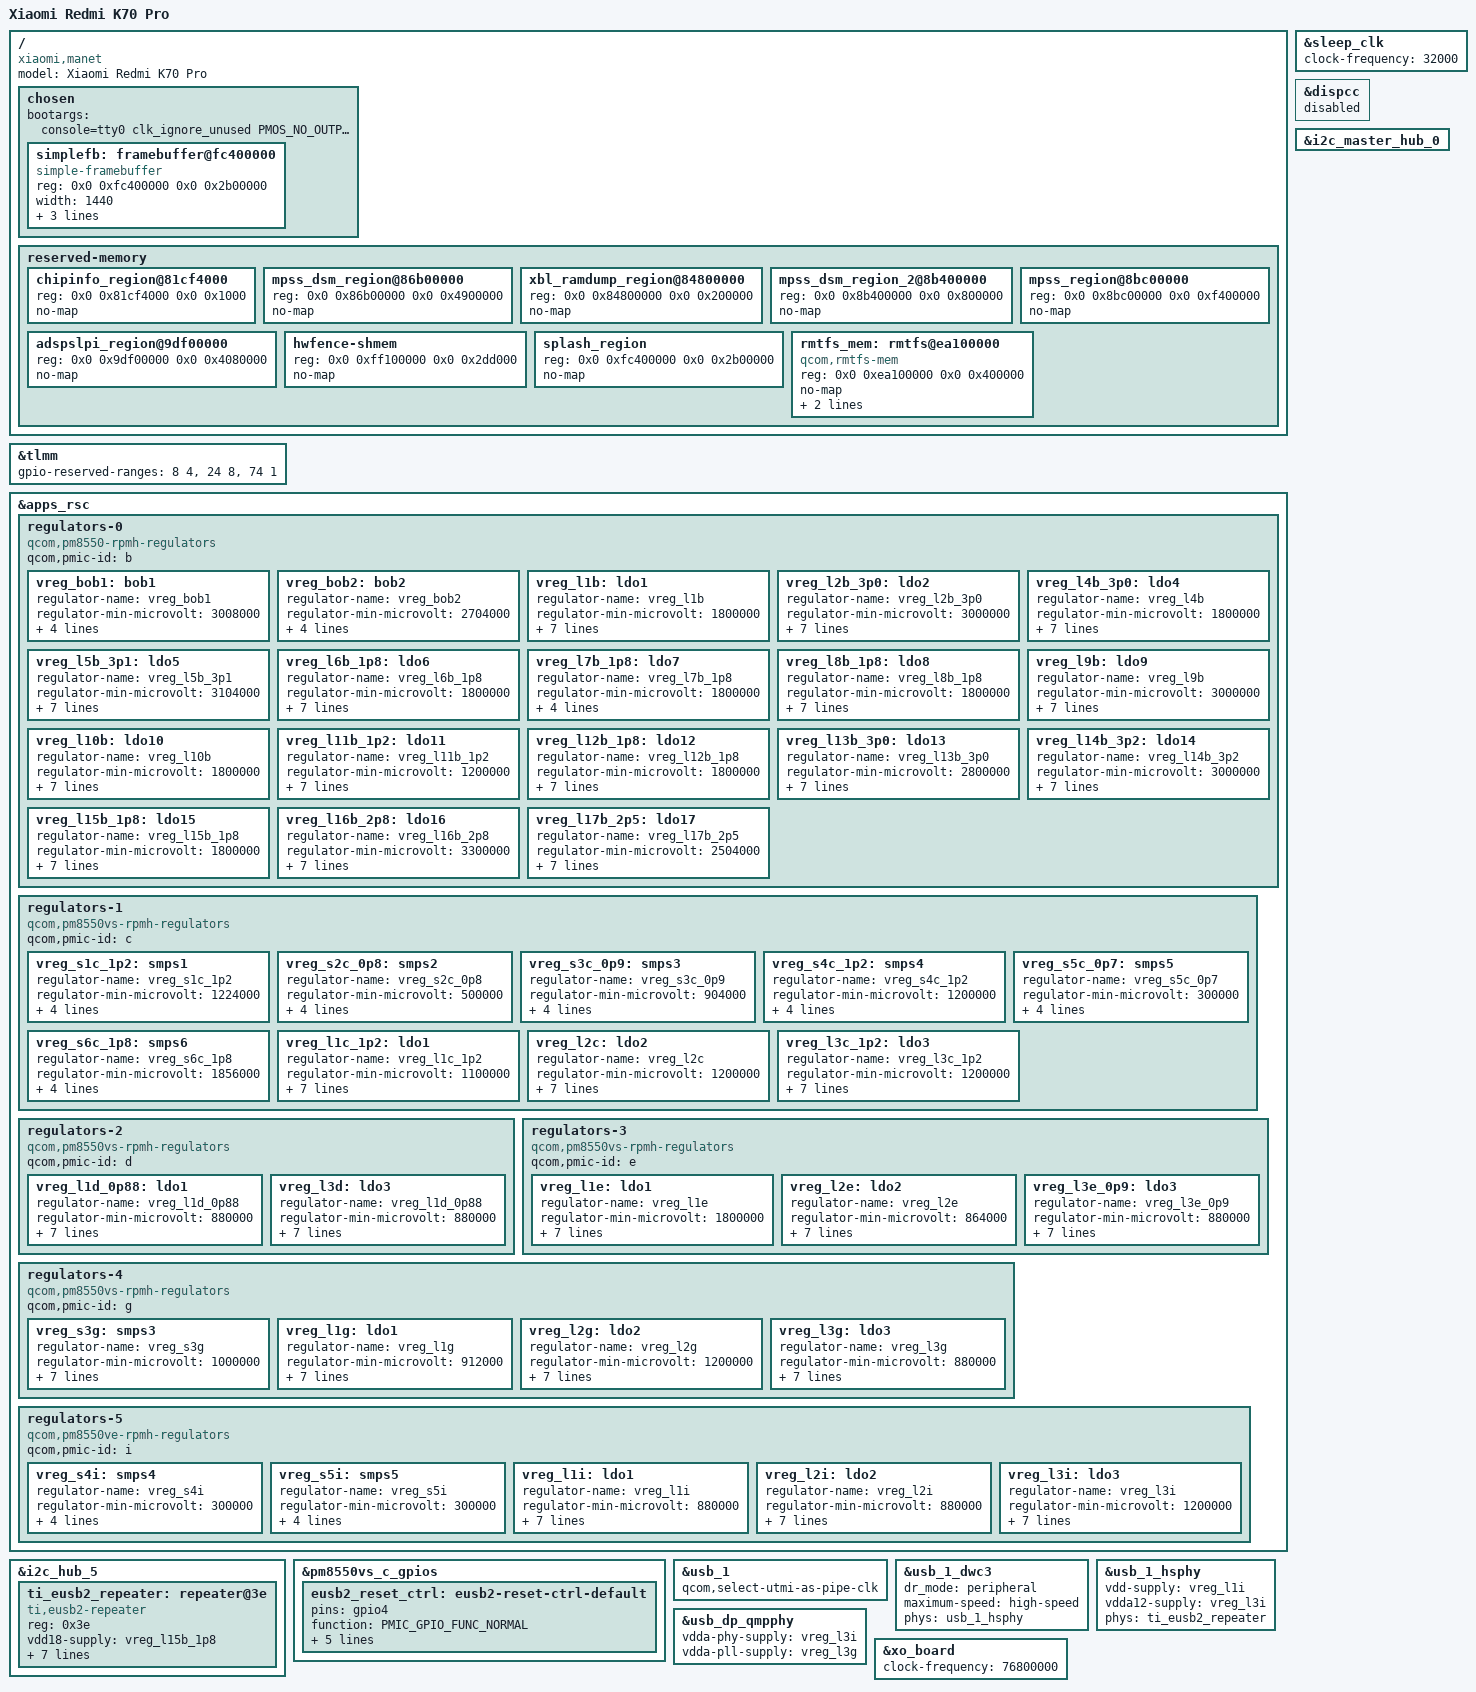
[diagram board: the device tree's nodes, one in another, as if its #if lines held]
// SPDX-License-Identifier: BSD-3-Clause
/*
 * Copyright (c) 2024, Igor Belwon <ibelwon@protonmail.com>
 */

/dts-v1/;

#include <dt-bindings/pinctrl/qcom,pmic-gpio.h>
#include <dt-bindings/regulator/qcom,rpmh-regulator.h>
#include "sm8650.dtsi"
#include "pm8550.dtsi"
#define PMK8550VE_SID 8
#include "pm8550ve.dtsi"
#include "pm8550vs.dtsi"
#include "pmk8550.dtsi"
#include "pmr735d_a.dtsi"

/delete-node/ &hwfence_shbuf;
/delete-node/ &rmtfs_mem;

#define ENABLE_SIMPLEFB true 

/ {
        model = "Xiaomi Redmi K70 Pro";
        compatible = "xiaomi,manet", "qcom,sm8650";

        chosen {
                #address-cells = <2>;
                #size-cells = <2>;
                ranges;

                bootargs = "console=tty0 clk_ignore_unused PMOS_NO_OUTPUT_REDIRECT";

#if ENABLE_SIMPLEFB
                simplefb: framebuffer@fc400000 {
                        compatible = "simple-framebuffer";
                        reg = <0x0 0xfc400000 0x0 0x2b00000>;
                        width = <1440>;
                        height = <3200>;
                        stride = <(1440 * 4)>;
                        format = "a8r8g8b8";
                };
#endif
        };

        reserved-memory {
                chipinfo_region@81cf4000 {
                    reg = <0x0 0x81cf4000 0x0 0x1000>;
                    no-map;
                };

                mpss_dsm_region@86b00000 {
                    reg = <0x0 0x86b00000 0x0 0x4900000>;
                    no-map;
                };

                xbl_ramdump_region@84800000 {
                    reg = <0x0 0x84800000 0x0 0x200000>;
                    no-map;
                };

                mpss_dsm_region_2@8b400000 {
                    reg = <0x0 0x8b400000 0x0 0x800000>;
                    no-map;
                };

                mpss_region@8bc00000 {
                    reg = <0x0 0x8bc00000 0x0 0xf400000>;
                    no-map;
                };

                adspslpi_region@9df00000 {
                    reg = <0x0 0x9df00000 0x0 0x4080000>;
                    no-map;
                };

                hwfence-shmem {
                    reg = <0x0 0xff100000 0x0 0x2dd000>;
                    no-map;
                };

                /* Hack for simplefb */
                splash_region {
                    reg = <0x0 0xfc400000 0x0 0x2b00000>;
                    no-map;
                };

                rmtfs_mem: rmtfs@ea100000 {
                    compatible = "qcom,rmtfs-mem";
                    reg = <0x0 0xea100000 0x0 0x400000>;
                    no-map;

                    qcom,client-id = <1>;
                    qcom,vmid = <QCOM_SCM_VMID_MSS_MSA>;
                };
        };
};

&sleep_clk {
	clock-frequency = <32000>;
};

&tlmm {
	gpio-reserved-ranges = <8 4>, <24 8>, <74 1>;
};

&apps_rsc {
	regulators-0 {
		compatible = "qcom,pm8550-rpmh-regulators";
		qcom,pmic-id = "b";

		vreg_bob1: bob1 {
			regulator-name = "vreg_bob1";
			regulator-min-microvolt = <3008000>;
			regulator-max-microvolt = <3960000>;
			regulator-initial-mode = <RPMH_REGULATOR_MODE_HPM>;
			regulator-always-on;
		};

		vreg_bob2: bob2 {
			regulator-name = "vreg_bob2";
			regulator-min-microvolt = <2704000>;
			regulator-max-microvolt = <3008000>;
			regulator-initial-mode = <RPMH_REGULATOR_MODE_HPM>;
			regulator-always-on;
		};

		vreg_l1b: ldo1 {
			regulator-name = "vreg_l1b";
			regulator-min-microvolt = <1800000>;
			regulator-max-microvolt = <1800000>;
			regulator-initial-mode = <RPMH_REGULATOR_MODE_HPM>;
			regulator-allow-set-load;
			regulator-allowed-modes = <RPMH_REGULATOR_MODE_LPM
						   RPMH_REGULATOR_MODE_HPM>;
			regulator-always-on;
		};

		vreg_l2b_3p0: ldo2 {
			regulator-name = "vreg_l2b_3p0";
			regulator-min-microvolt = <3000000>;
			regulator-max-microvolt = <3010000>;
			regulator-initial-mode = <RPMH_REGULATOR_MODE_HPM>;
			regulator-allow-set-load;
			regulator-allowed-modes = <RPMH_REGULATOR_MODE_LPM
						   RPMH_REGULATOR_MODE_HPM>;
			regulator-always-on;
		};

		vreg_l4b_3p0: ldo4 {
			regulator-name = "vreg_l4b";
			regulator-min-microvolt = <1800000>;
			regulator-max-microvolt = <1800000>;
			regulator-initial-mode = <RPMH_REGULATOR_MODE_HPM>;
			regulator-allow-set-load;
			regulator-allowed-modes = <RPMH_REGULATOR_MODE_LPM
						   RPMH_REGULATOR_MODE_HPM>;
			regulator-always-on;
		};

		vreg_l5b_3p1: ldo5 {
			regulator-name = "vreg_l5b_3p1";
			regulator-min-microvolt = <3104000>;
			regulator-max-microvolt = <3104000>;
			regulator-initial-mode = <RPMH_REGULATOR_MODE_HPM>;
			regulator-allow-set-load;
			regulator-allowed-modes = <RPMH_REGULATOR_MODE_LPM
						   RPMH_REGULATOR_MODE_HPM>;
			regulator-always-on;
		};

		vreg_l6b_1p8: ldo6 {
			regulator-name = "vreg_l6b_1p8";
			regulator-min-microvolt = <1800000>;
			regulator-max-microvolt = <3008000>;
			regulator-initial-mode = <RPMH_REGULATOR_MODE_HPM>;
			regulator-allow-set-load;
			regulator-allowed-modes = <RPMH_REGULATOR_MODE_LPM
						   RPMH_REGULATOR_MODE_HPM>;
			regulator-always-on;
		};

		vreg_l7b_1p8: ldo7 {
			regulator-name = "vreg_l7b_1p8";
			regulator-min-microvolt = <1800000>;
			regulator-max-microvolt = <3008000>;
			regulator-initial-mode = <RPMH_REGULATOR_MODE_HPM>;
			regulator-always-on;
		};

		vreg_l8b_1p8: ldo8 {
			regulator-name = "vreg_l8b_1p8";
			regulator-min-microvolt = <1800000>;
			regulator-max-microvolt = <1810000>;
			regulator-initial-mode = <RPMH_REGULATOR_MODE_HPM>;
			regulator-allow-set-load;
			regulator-allowed-modes = <RPMH_REGULATOR_MODE_LPM
						   RPMH_REGULATOR_MODE_HPM>;
			regulator-always-on;
		};

		vreg_l9b: ldo9 {
			regulator-name = "vreg_l9b";
			regulator-min-microvolt = <3000000>;
			regulator-max-microvolt = <3000000>;
			regulator-initial-mode = <RPMH_REGULATOR_MODE_HPM>;
			regulator-allow-set-load;
			regulator-allowed-modes = <RPMH_REGULATOR_MODE_LPM
						   RPMH_REGULATOR_MODE_HPM>;
			regulator-always-on;
		};

		vreg_l10b: ldo10 {
			regulator-name = "vreg_l10b";
			regulator-min-microvolt = <1800000>;
			regulator-max-microvolt = <1800000>;
			regulator-initial-mode = <RPMH_REGULATOR_MODE_HPM>;
			regulator-allow-set-load;
			regulator-allowed-modes = <RPMH_REGULATOR_MODE_LPM
						   RPMH_REGULATOR_MODE_HPM>;
			regulator-always-on;
		};

		vreg_l11b_1p2: ldo11 {
			regulator-name = "vreg_l11b_1p2";
			regulator-min-microvolt = <1200000>;
			regulator-max-microvolt = <1200000>;
			regulator-initial-mode = <RPMH_REGULATOR_MODE_HPM>;
			regulator-allow-set-load;
			regulator-allowed-modes = <RPMH_REGULATOR_MODE_LPM
						   RPMH_REGULATOR_MODE_HPM>;
			regulator-always-on;
		};

		vreg_l12b_1p8: ldo12 {
			regulator-name = "vreg_l12b_1p8";
			regulator-min-microvolt = <1800000>;
			regulator-max-microvolt = <1800000>;
			regulator-initial-mode = <RPMH_REGULATOR_MODE_HPM>;
			regulator-allow-set-load;
			regulator-allowed-modes = <RPMH_REGULATOR_MODE_LPM
						   RPMH_REGULATOR_MODE_HPM>;
			regulator-always-on;
		};

		vreg_l13b_3p0: ldo13 {
			regulator-name = "vreg_l13b_3p0";
			regulator-min-microvolt = <2800000>;
			regulator-max-microvolt = <2800000>;
			regulator-initial-mode = <RPMH_REGULATOR_MODE_HPM>;
			regulator-allow-set-load;
			regulator-allowed-modes = <RPMH_REGULATOR_MODE_LPM
						   RPMH_REGULATOR_MODE_HPM>;
			regulator-always-on;
		};

		vreg_l14b_3p2: ldo14 {
			regulator-name = "vreg_l14b_3p2";
			regulator-min-microvolt = <3000000>;
			regulator-max-microvolt = <3000000>;
			regulator-initial-mode = <RPMH_REGULATOR_MODE_HPM>;
			regulator-allow-set-load;
			regulator-allowed-modes = <RPMH_REGULATOR_MODE_LPM
						   RPMH_REGULATOR_MODE_HPM>;
			regulator-always-on;
		};

		vreg_l15b_1p8: ldo15 {
			regulator-name = "vreg_l15b_1p8";
			regulator-min-microvolt = <1800000>;
			regulator-max-microvolt = <1800000>;
			regulator-initial-mode = <RPMH_REGULATOR_MODE_HPM>;
			regulator-allow-set-load;
			regulator-allowed-modes = <RPMH_REGULATOR_MODE_LPM
						   RPMH_REGULATOR_MODE_HPM>;
			regulator-always-on;
		};

		vreg_l16b_2p8: ldo16 {
			regulator-name = "vreg_l16b_2p8";
			regulator-min-microvolt = <3300000>;
			regulator-max-microvolt = <3300000>;
			regulator-initial-mode = <RPMH_REGULATOR_MODE_HPM>;
			regulator-allow-set-load;
			regulator-allowed-modes = <RPMH_REGULATOR_MODE_LPM
						   RPMH_REGULATOR_MODE_HPM>;
			regulator-always-on;
		};

		vreg_l17b_2p5: ldo17 {
			regulator-name = "vreg_l17b_2p5";
			regulator-min-microvolt = <2504000>;
			regulator-max-microvolt = <2504000>;
			regulator-initial-mode = <RPMH_REGULATOR_MODE_HPM>;
			regulator-allow-set-load;
			regulator-allowed-modes = <RPMH_REGULATOR_MODE_LPM
						   RPMH_REGULATOR_MODE_HPM>;
			regulator-always-on;
		};
	};

	regulators-1 {
		compatible = "qcom,pm8550vs-rpmh-regulators";
		qcom,pmic-id = "c";

		vreg_s1c_1p2: smps1 {
			regulator-name = "vreg_s1c_1p2";
			regulator-min-microvolt = <1224000>;
			regulator-max-microvolt = <1348000>;
			regulator-initial-mode = <RPMH_REGULATOR_MODE_HPM>;
			regulator-always-on;
		};

		vreg_s2c_0p8: smps2 {
			regulator-name = "vreg_s2c_0p8";
			regulator-min-microvolt = <500000>;
			regulator-max-microvolt = <1036000>;
			regulator-initial-mode = <RPMH_REGULATOR_MODE_HPM>;
			regulator-always-on;
		};

		vreg_s3c_0p9: smps3 {
			regulator-name = "vreg_s3c_0p9";
			regulator-min-microvolt = <904000>;
			regulator-max-microvolt = <1064000>;
			regulator-initial-mode = <RPMH_REGULATOR_MODE_HPM>;
			regulator-always-on;
		};

		vreg_s4c_1p2: smps4 {
			regulator-name = "vreg_s4c_1p2";
			regulator-min-microvolt = <1200000>;
			regulator-max-microvolt = <1280000>;
			regulator-initial-mode = <RPMH_REGULATOR_MODE_HPM>;
			regulator-always-on;
		};

		vreg_s5c_0p7: smps5 {
			regulator-name = "vreg_s5c_0p7";
			regulator-min-microvolt = <300000>;
			regulator-max-microvolt = <900000>;
			regulator-initial-mode = <RPMH_REGULATOR_MODE_HPM>;
			regulator-always-on;
		};

		vreg_s6c_1p8: smps6 {
			regulator-name = "vreg_s6c_1p8";
			regulator-min-microvolt = <1856000>;
			regulator-max-microvolt = <2000000>;
			regulator-initial-mode = <RPMH_REGULATOR_MODE_HPM>;
			regulator-always-on;
		};

		vreg_l1c_1p2: ldo1 {
			regulator-name = "vreg_l1c_1p2";
			regulator-min-microvolt = <1100000>;
			regulator-max-microvolt = <1200000>;
			regulator-initial-mode = <RPMH_REGULATOR_MODE_HPM>;
			regulator-allow-set-load;
			regulator-allowed-modes = <RPMH_REGULATOR_MODE_LPM
						   RPMH_REGULATOR_MODE_HPM>;
			regulator-always-on;
		};

		vreg_l2c: ldo2 {
			regulator-name = "vreg_l2c";
			regulator-min-microvolt = <1200000>;
			regulator-max-microvolt = <1200000>;
			regulator-initial-mode = <RPMH_REGULATOR_MODE_HPM>;
			regulator-allow-set-load;
			regulator-allowed-modes = <RPMH_REGULATOR_MODE_LPM
						   RPMH_REGULATOR_MODE_HPM>;
			regulator-always-on;
		};

		vreg_l3c_1p2: ldo3 {
			regulator-name = "vreg_l3c_1p2";
			regulator-min-microvolt = <1200000>;
			regulator-max-microvolt = <1200000>;
			regulator-initial-mode = <RPMH_REGULATOR_MODE_HPM>;
			regulator-allow-set-load;
			regulator-allowed-modes = <RPMH_REGULATOR_MODE_LPM
						   RPMH_REGULATOR_MODE_HPM>;
			regulator-always-on;
		};
	};

	regulators-2 {
		compatible = "qcom,pm8550vs-rpmh-regulators";
		qcom,pmic-id = "d";

		vreg_l1d_0p88: ldo1 {
			regulator-name = "vreg_l1d_0p88";
			regulator-min-microvolt = <880000>;
			regulator-max-microvolt = <920000>;
			regulator-initial-mode = <RPMH_REGULATOR_MODE_HPM>;
			regulator-allow-set-load;
			regulator-allowed-modes = <RPMH_REGULATOR_MODE_LPM
						   RPMH_REGULATOR_MODE_HPM>;
			regulator-always-on;
		};

		vreg_l3d: ldo3 {
			regulator-name = "vreg_l1d_0p88";
			regulator-min-microvolt = <880000>;
			regulator-max-microvolt = <920000>;
			regulator-initial-mode = <RPMH_REGULATOR_MODE_HPM>;
			regulator-allow-set-load;
			regulator-allowed-modes = <RPMH_REGULATOR_MODE_LPM
						   RPMH_REGULATOR_MODE_HPM>;
			regulator-always-on;
		};
	};

	regulators-3 {
		compatible = "qcom,pm8550vs-rpmh-regulators";
		qcom,pmic-id = "e";

		vreg_l1e: ldo1 {
			regulator-name = "vreg_l1e";
			regulator-min-microvolt = <1800000>;
			regulator-max-microvolt = <1800000>;
			regulator-initial-mode = <RPMH_REGULATOR_MODE_HPM>;
			regulator-allow-set-load;
			regulator-allowed-modes = <RPMH_REGULATOR_MODE_LPM
						   RPMH_REGULATOR_MODE_HPM>;
			regulator-always-on;
		};

		vreg_l2e: ldo2 {
			regulator-name = "vreg_l2e";
			regulator-min-microvolt = <864000>;
			regulator-max-microvolt = <972000>;
			regulator-initial-mode = <RPMH_REGULATOR_MODE_HPM>;
			regulator-allow-set-load;
			regulator-allowed-modes = <RPMH_REGULATOR_MODE_LPM
						   RPMH_REGULATOR_MODE_HPM>;
			regulator-always-on;
		};

		vreg_l3e_0p9: ldo3 {
			regulator-name = "vreg_l3e_0p9";
			regulator-min-microvolt = <880000>;
			regulator-max-microvolt = <920000>;
			regulator-initial-mode = <RPMH_REGULATOR_MODE_HPM>;
			regulator-allow-set-load;
			regulator-allowed-modes = <RPMH_REGULATOR_MODE_LPM
						   RPMH_REGULATOR_MODE_HPM>;
			regulator-always-on;
		};
	};

	regulators-4 {
		compatible = "qcom,pm8550vs-rpmh-regulators";
		qcom,pmic-id = "g";

		vreg_s3g: smps3 {
			regulator-name = "vreg_s3g";
			regulator-min-microvolt = <1000000>;
			regulator-max-microvolt = <1100000>;
			regulator-initial-mode = <RPMH_REGULATOR_MODE_HPM>;
			regulator-allow-set-load;
			regulator-allowed-modes = <RPMH_REGULATOR_MODE_LPM
						   RPMH_REGULATOR_MODE_HPM>;
			regulator-always-on;
		};

		vreg_l1g: ldo1 {
			regulator-name = "vreg_l1g";
			regulator-min-microvolt = <912000>;
			regulator-max-microvolt = <920000>;
			regulator-initial-mode = <RPMH_REGULATOR_MODE_HPM>;
			regulator-allow-set-load;
			regulator-allowed-modes = <RPMH_REGULATOR_MODE_LPM
						   RPMH_REGULATOR_MODE_HPM>;
			regulator-always-on;
		};

		vreg_l2g: ldo2 {
			regulator-name = "vreg_l2g";
			regulator-min-microvolt = <1200000>;
			regulator-max-microvolt = <1200000>;
			regulator-initial-mode = <RPMH_REGULATOR_MODE_HPM>;
			regulator-allow-set-load;
			regulator-allowed-modes = <RPMH_REGULATOR_MODE_LPM
						   RPMH_REGULATOR_MODE_HPM>;
			regulator-always-on;
		};

		vreg_l3g: ldo3 {
			regulator-name = "vreg_l3g";
			regulator-min-microvolt = <880000>;
			regulator-max-microvolt = <912000>;
			regulator-initial-mode = <RPMH_REGULATOR_MODE_HPM>;
			regulator-allow-set-load;
			regulator-allowed-modes = <RPMH_REGULATOR_MODE_LPM
						   RPMH_REGULATOR_MODE_HPM>;
			regulator-always-on;
		};
	};

	regulators-5 {
		compatible = "qcom,pm8550ve-rpmh-regulators";
		qcom,pmic-id = "i";

		vreg_s4i: smps4 {
			regulator-name = "vreg_s4i";
			regulator-min-microvolt = <300000>;
			regulator-max-microvolt = <1004000>;
			regulator-initial-mode = <RPMH_REGULATOR_MODE_HPM>;
			regulator-always-on;
		};

		vreg_s5i: smps5 {
			regulator-name = "vreg_s5i";
			regulator-min-microvolt = <300000>;
			regulator-max-microvolt = <1004000>;
			regulator-initial-mode = <RPMH_REGULATOR_MODE_HPM>;
			regulator-always-on;
		};

		vreg_l1i: ldo1 {
			regulator-name = "vreg_l1i";
			regulator-min-microvolt = <880000>;
			regulator-max-microvolt = <912000>;
			regulator-initial-mode = <RPMH_REGULATOR_MODE_HPM>;
			regulator-allow-set-load;
			regulator-allowed-modes = <RPMH_REGULATOR_MODE_LPM
						   RPMH_REGULATOR_MODE_HPM>;
			regulator-always-on;
		};

		vreg_l2i: ldo2 {
			regulator-name = "vreg_l2i";
			regulator-min-microvolt = <880000>;
			regulator-max-microvolt = <912000>;
			regulator-initial-mode = <RPMH_REGULATOR_MODE_HPM>;
			regulator-allow-set-load;
			regulator-allowed-modes = <RPMH_REGULATOR_MODE_LPM
						   RPMH_REGULATOR_MODE_HPM>;
			regulator-always-on;
		};

		vreg_l3i: ldo3 {
			regulator-name = "vreg_l3i";
			regulator-min-microvolt = <1200000>;
			regulator-max-microvolt = <1200000>;
			regulator-initial-mode = <RPMH_REGULATOR_MODE_HPM>;
			regulator-allow-set-load;
			regulator-allowed-modes = <RPMH_REGULATOR_MODE_LPM
						   RPMH_REGULATOR_MODE_HPM>;
			regulator-always-on;
		};
	};
};

#if ENABLE_SIMPLEFB
&dispcc {
	status = "disabled";
};
#endif

&i2c_master_hub_0 {
	status = "okay";
};

&i2c_hub_5 {
	status = "okay";

	ti_eusb2_repeater: repeater@3e {
		#phy-cells = <0>;
		compatible = "ti,eusb2-repeater";
		reg = <0x3e>;
		vdd18-supply = <&vreg_l15b_1p8>;
		vdd3-supply = <&vreg_l5b_3p1>;
		reset-gpio = <&pm8550vs_c_gpios 4 GPIO_ACTIVE_HIGH>;
		pinctrl-names = "default";
		pinctrl-0 = <&eusb2_reset_ctrl>;
		qcom,param-host-override-seq = <0x00 0x50 0x06 0x51 0x01 0x52 0x07 0x53 0x03 0x54 0x00 0x55 0x00 0x56 0x04 0x57 0x02 0x58 0x03 0x59 0x01 0x5a 0x02 0x5b>;
		qcom,param-override-seq = <0x00 0x50 0x0f 0x51 0x04 0x52 0x07 0x53 0x03 0x54 0x01 0x55 0x00 0x56 0x07 0x57 0x02 0x58 0x03 0x59 0x01 0x5a 0x02 0x5b>;
	};
};

&pm8550vs_c_gpios {
	eusb2_reset_ctrl: eusb2-reset-ctrl-default {
		pins = "gpio4";
		function = PMIC_GPIO_FUNC_NORMAL;
		input-enable;
		output-enable;
		bias-disable;
		power-source = <1>;
		qcom,drive-strength = <PMIC_GPIO_STRENGTH_MED>;
	};
};

&usb_1 {
	/* USB 2.0 only for now */
	qcom,select-utmi-as-pipe-clk;
	status = "okay";
};

&usb_1_dwc3 {
	dr_mode = "peripheral";
	maximum-speed = "high-speed";
	/* Remove USB3 phy */
	phys = <&usb_1_hsphy>;
	phy-names = "usb2-phy";
};

&usb_1_hsphy {
	vdd-supply = <&vreg_l1i>;
	vdda12-supply = <&vreg_l3i>;

	phys = <&ti_eusb2_repeater>;

	status = "okay";
};

&usb_dp_qmpphy {
	vdda-phy-supply = <&vreg_l3i>;
	vdda-pll-supply = <&vreg_l3g>;

	status = "okay";
};

&xo_board {
	clock-frequency = <76800000>;
};
